# MSP430FR2433 register map
Registers are 16-bit, read-write, reset 0x0 unless marked. A register's access mark holds for its fields unless they carry their own. Offsets are from the block's base; [hi:lo] are bit positions; {n}, {i} and the like mark numbered series; 'fields as' and 'values as' point back to an identical list.

## TIMER_3_A2
Base 0x00000440
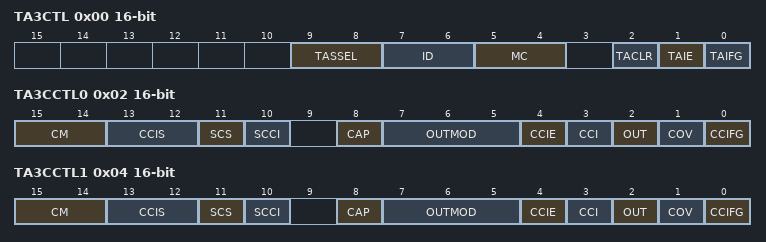
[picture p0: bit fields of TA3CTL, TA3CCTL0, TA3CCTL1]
0x00 TA3CTL — Timer3_A2 Control
  [9:8] TASSEL — Timer A clock source select 1
    0=Timer A clock source select: 0 - TACLK; 1=Timer A clock source select: 1 - ACLK; 2=Timer A clock source select: 2 - SMCLK; 3=Timer A clock source select: 3 - INCLK
  [7:6] ID — Timer A clock input divider 1
    0=Timer A input divider: 0 - /1; 1=Timer A input divider: 1 - /2; 2=Timer A input divider: 2 - /4; 3=Timer A input divider: 3 - /8
  [5:4] MC — Timer A mode control 1
    0=Timer A mode control: 0 - Stop; 1=Timer A mode control: 1 - Up to CCR0; 2=Timer A mode control: 2 - Continuous up; 3=Timer A mode control: 3 - Up/Down
  [2] TACLR — Timer A counter clear
  [1] TAIE — Timer A counter interrupt enable
  [0] TAIFG — Timer A counter interrupt flag
0x02 TA3CCTL0 — Timer3_A2 Capture/Compare Control 0
  [15:14] CM — Capture mode 1
    0=Capture mode: 0 - disabled; 1=Capture mode: 1 - pos. edge; 2=Capture mode: 1 - neg. edge; 3=Capture mode: 1 - both edges
  [13:12] CCIS — Capture input select 1
    0=Capture input select: 0 - CCIxA; 1=Capture input select: 1 - CCIxB; 2=Capture input select: 2 - GND; 3=Capture input select: 3 - Vcc
  [11] SCS — Capture sychronize
  [10] SCCI — Latched capture signal (read)
  [8] CAP — Capture mode: 1 /Compare mode : 0
  [7:5] OUTMOD — Output mode 2
    0=PWM output mode: 0 - output only; 1=PWM output mode: 1 - set; 2=PWM output mode: 2 - PWM toggle/reset; 3=PWM output mode: 3 - PWM set/reset; 4=PWM output mode: 4 - toggle; 5=PWM output mode: 5 - Reset; 6=PWM output mode: 6 - PWM toggle/set; 7=PWM output mode: 7 - PWM reset/set
  [4] CCIE — Capture/compare interrupt enable
  [3] CCI — Capture input signal (read)
  [2] OUT — PWM Output signal if output mode 0
  [1] COV — Capture/compare overflow flag
  [0] CCIFG — Capture/compare interrupt flag
0x04 TA3CCTL1 — Timer3_A2 Capture/Compare Control 1
  fields as TA3CCTL0
0x10 TA3R — Timer3_A2
0x12 TA3CCR0 — Timer3_A2 Capture/Compare 0
0x14 TA3CCR1 — Timer3_A2 Capture/Compare 1
0x20 TA3EX0 — Timer3_A2 Expansion Register 0
  [2:0] TAIDEX — Timer A Input divider expansion Bit: 0
    {v}=Timer A Input divider expansion : /{v+1} (v=0..7)
0x2E TA3IV — Timer3_A2 Interrupt Vector Word

## MPY_16 — MPY 16 Multiplier 16 Bit Mode
Base 0x000004C0
0x00 MPY — Multiply Unsigned/Operand 1
0x02 MPYS — Multiply Signed/Operand 1
0x04 MAC — Multiply Unsigned and Accumulate/Operand 1
0x06 MACS — Multiply Signed and Accumulate/Operand 1
0x08 OP2 — Operand 2
0x0A RESLO — Result Low Word
0x0C RESHI — Result High Word
0x0E SUMEXT — Sum Extend
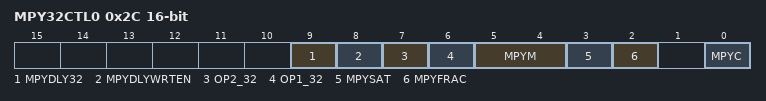
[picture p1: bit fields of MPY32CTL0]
0x2C MPY32CTL0 — MPY32 Control Register 0
  [9] MPYDLY32 — Delayed write mode
  [8] MPYDLYWRTEN — Delayed write enable
  [7] OP2_32 — Bit-width of operand 2 0:16Bit / 1:32Bit
  [6] OP1_32 — Bit-width of operand 1 0:16Bit / 1:32Bit
  [5:4] MPYM — Multiplier mode Bit:0
    0=Multiplier mode: MPY; 1=Multiplier mode: MPYS; 2=Multiplier mode: MAC; 3=Multiplier mode: MACS
  [3] MPYSAT — Saturation mode
  [2] MPYFRAC — Fractional mode
  [0] MPYC — Carry of the multiplier

## MPY_32 — MPY 32 Multiplier 32 Bit Mode
Base 0x000004D0
0x00 MPY32L — 32-bit operand 1 - multiply - low word
0x02 MPY32H — 32-bit operand 1 - multiply - high word
0x04 MPYS32L — 32-bit operand 1 - signed multiply - low word
0x06 MPYS32H — 32-bit operand 1 - signed multiply - high word
0x08 MAC32L — 32-bit operand 1 - multiply accumulate - low word
0x0A MAC32H — 32-bit operand 1 - multiply accumulate - high word
0x0C MACS32L — 32-bit operand 1 - signed multiply accumulate - low word
0x0E MACS32H — 32-bit operand 1 - signed multiply accumulate - high word
0x10 OP2L — 32-bit operand 2 - low word
0x12 OP2H — 32-bit operand 2 - high word
0x14 RES0 — 32x32-bit result 0 - least significant word
0x16 RES1 — 32x32-bit result 1
0x18 RES2 — 32x32-bit result 2
0x1A RES3 — 32x32-bit result 3 - most significant word

## BACKUP_MEMORY
Base 0x00000660
{0x0+2i} BAKMEM{i} (i=0..15) — Battery Backup Memory {i}

## ADC
Base 0x00000700
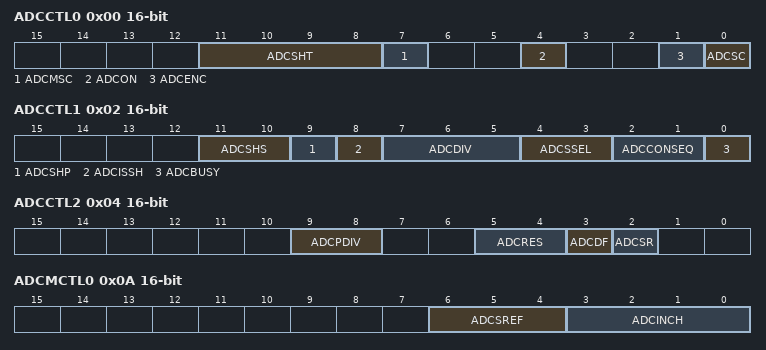
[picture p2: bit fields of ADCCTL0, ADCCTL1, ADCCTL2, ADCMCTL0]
0x00 ADCCTL0 — ADC Control 0
  [11:8] ADCSHT — ADC Sample Hold Select Bit: 0
    {v}=ADC Sample Hold Select {v} (v=0..15)
  [7] ADCMSC — ADC Multiple SampleConversion
  [4] ADCON — ADC On/enable
  [1] ADCENC — ADC Enable Conversion
  [0] ADCSC — ADC Start Conversion
0x02 ADCCTL1 — ADC Control 1
  [11:10] ADCSHS — ADC Sample/Hold Source 0
    {v}=ADC Sample/Hold Source: {v} (v=0..3)
  [9] ADCSHP — ADC Sample/Hold Pulse Mode
  [8] ADCISSH — ADC Invert Sample Hold Signal
  [7:5] ADCDIV — ADC Clock Divider Select 0
    {v}=ADC Clock Divider Select: {v} (v=0..7)
  [4:3] ADCSSEL — ADC Clock Source Select 0
    {v}=ADC Clock Source Select: {v} (v=0..3)
  [2:1] ADCCONSEQ — ADC Conversion Sequence Select 0
    {v}=ADC Conversion Sequence Select: {v} (v=0..3)
  [0] ADCBUSY
0x04 ADCCTL2 — ADC Control 2
  [9:8] ADCPDIV — ADC predivider Bit: 0
    0=ADC predivider /1; 1=ADC predivider /2; 2=ADC predivider /64; 3=ADC predivider reserved
  [5:4] ADCRES — ADC Resolution
    0=8 bit; 1=10 bit
  [3] ADCDF — ADC Data Format
  [2] ADCSR — ADC Sampling Rate
0x06 ADCLO — ADC Window Comparator High Threshold
0x08 ADCHI — ADC Window Comparator High Threshold
0x0A ADCMCTL0 — ADC Memory Control 0
  [6:4] ADCSREF — ADC Select Reference Bit 0
    {v}=ADC Select Reference {v} (v=0..7)
  [3:0] ADCINCH — ADC Input Channel Select Bit 0
    {v}=ADC Input Channel {v} (v=0..15)
0x12 ADCMEM0 — ADC Conversion Memory 0
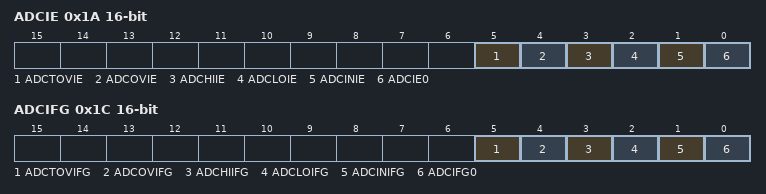
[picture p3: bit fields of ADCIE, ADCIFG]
0x1A ADCIE — ADC Interrupt Enable
  [5] ADCTOVIE — ADC conversion-time-overflow Interrupt enable
  [4] ADCOVIE — ADC ADCMEM overflow Interrupt enable
  [3] ADCHIIE — ADC Interrupt enable for upper threshold of the Window comparator
  [2] ADCLOIE — ADC Interrupt enable for lower threshold of the Window comparator
  [1] ADCINIE — ADC Interrupt enable for the inside of window of the Window comparator
  [0] ADCIE0 — ADC Interrupt enable
0x1C ADCIFG — ADC Interrupt Flag
  [5] ADCTOVIFG — ADC conversion-time-overflow Interrupt Flag
  [4] ADCOVIFG — ADC ADCMEM overflow Interrupt Flag
  [3] ADCHIIFG — ADC Interrupt Flag for upper threshold of the Window comparator
  [2] ADCLOIFG — ADC Interrupt Flag for lower threshold of the Window comparator
  [1] ADCINIFG — ADC Interrupt Flag for the inside of window of the Window comparator
  [0] ADCIFG0 — ADC Interrupt Flag
0x1E ADCIV — ADC Interrupt Vector Word
